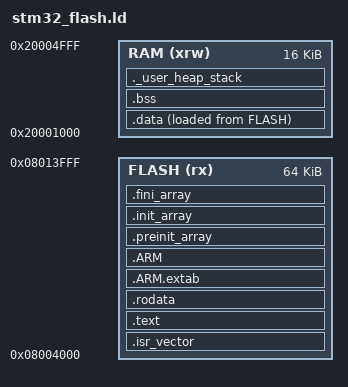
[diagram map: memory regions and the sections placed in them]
/* Entry Point */
ENTRY(Reset_Handler)

/* Highest address of the user mode stack */
_estack = 0x20005000;    /* end of RAM (20KB at 0x20000000, but app uses 0x20001000-0x20005000) */

/* Generate a link error if heap and stack don't fit into RAM */
_Min_Heap_Size = 0x200;  /* required amount of heap  */
_Min_Stack_Size = 0x400; /* required amount of stack */

/* Specify the memory areas */
MEMORY
{
  RAM (xrw)      : ORIGIN = 0x20001000, LENGTH = 16K
  FLASH (rx)     : ORIGIN = 0x08004000, LENGTH = 64K
}

/* Define output sections */
SECTIONS
{
  /* The startup code goes first into FLASH */
  .isr_vector :
  {
    . = ALIGN(4);
    KEEP(*(.isr_vector)) /* Startup code */
    . = ALIGN(4);
  } >FLASH

  /* The program code and other data goes into FLASH */
  .text :
  {
    . = ALIGN(4);
    *(.text)           /* .text sections (code) */
    *(.text*)          /* .text* sections (code) */
    *(.glue_7)         /* glue arm to thumb code */
    *(.glue_7t)        /* glue thumb to arm code */
    *(.eh_frame)

    KEEP (*(.init))
    KEEP (*(.fini))

    . = ALIGN(4);
    _etext = .;        /* define a global symbols at end of code */
  } >FLASH

  /* Constant data goes into FLASH */
  .rodata :
  {
    . = ALIGN(4);
    *(.rodata)         /* .rodata sections (constants, strings, etc.) */
    *(.rodata*)        /* .rodata* sections (constants, strings, etc.) */
    . = ALIGN(4);
  } >FLASH

  .ARM.extab   : { *(.ARM.extab* .gnu.linkonce.armextab.*) } >FLASH
  .ARM : {
    __exidx_start = .;
    *(.ARM.exidx*)
    __exidx_end = .;
  } >FLASH

  .preinit_array     :
  {
    PROVIDE_HIDDEN (__preinit_array_start = .);
    KEEP (*(.preinit_array*))
    PROVIDE_HIDDEN (__preinit_array_end = .);
  } >FLASH
  
  .init_array :
  {
    PROVIDE_HIDDEN (__init_array_start = .);
    KEEP (*(SORT(.init_array.*)))
    KEEP (*(.init_array*))
    PROVIDE_HIDDEN (__init_array_end = .);
  } >FLASH
  
  .fini_array :
  {
    PROVIDE_HIDDEN (__fini_array_start = .);
    KEEP (*(SORT(.fini_array.*)))
    KEEP (*(.fini_array*))
    PROVIDE_HIDDEN (__fini_array_end = .);
  } >FLASH

  /* Application-specific symbols to avoid conflict with bootloader */
  _sidata_app = LOADADDR(.data);

  /* Initialized data sections goes into RAM, load LMA copy after code */
  .data : 
  {
    . = ALIGN(4);
    _sdata_app = .;        /* create a global symbol at data start */
    _sdata = .;            /* keep for compatibility */
    *(.data)               /* .data sections */
    *(.data*)              /* .data* sections */

    . = ALIGN(4);
    _edata_app = .;        /* define a global symbol at data end */
    _edata = .;            /* keep for compatibility */
  } >RAM AT> FLASH

  
  /* Uninitialized data section */
  . = ALIGN(4);
  .bss :
  {
    /* This is used by the startup in order to initialize the .bss secion */
    _sbss_app = .;         /* define a global symbol at bss start */
    _sbss = .;             /* keep for compatibility */
    __bss_start__ = _sbss_app;
    *(.bss)
    *(.bss*)
    *(COMMON)

    . = ALIGN(4);
    _ebss_app = .;         /* define a global symbol at bss end */
    _ebss = .;             /* keep for compatibility */
    __bss_end__ = _ebss_app;
  } >RAM

  /* User_heap_stack section, used to check that there is enough RAM left */
  ._user_heap_stack :
  {
    . = ALIGN(8);
    PROVIDE ( end = . );
    PROVIDE ( _end = . );
    . = . + _Min_Heap_Size;
    . = . + _Min_Stack_Size;
    . = ALIGN(8);
  } >RAM

  /* Remove information from the standard libraries */
  /DISCARD/ :
  {
    libc.a ( * )
    libm.a ( * )
    libgcc.a ( * )
  }

  .ARM.attributes 0 : { *(.ARM.attributes) }
}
